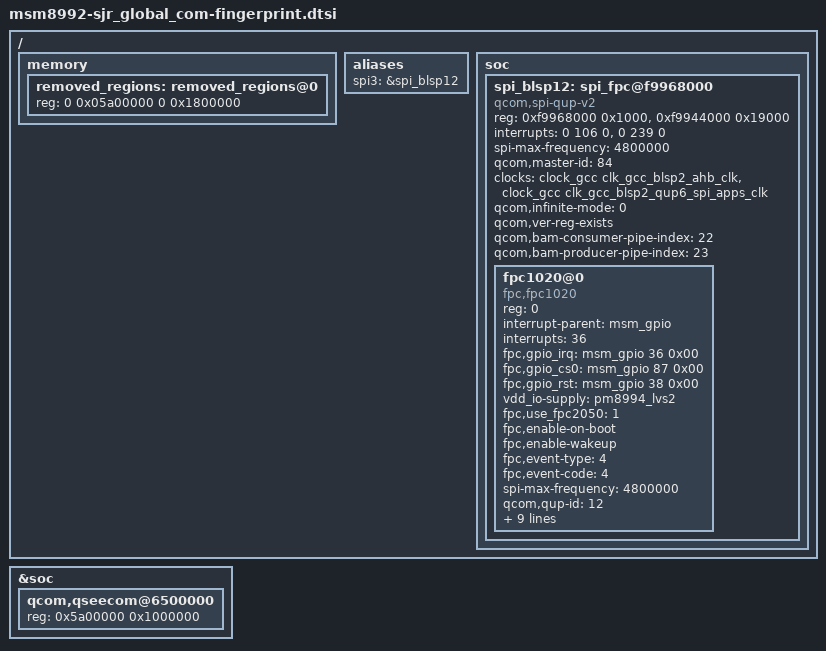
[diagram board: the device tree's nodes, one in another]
/*
 * Copyright (c) 2015, The Linux Foundation. All rights reserved.
 *
 * This program is free software; you can redistribute it and/or modify
 * it under the terms of the GNU General Public License version 2 and
 * only version 2 as published by the Free Software Foundation.
 *
 * This program is distributed in the hope that it will be useful,
 * but WITHOUT ANY WARRANTY; without even the implied warranty of
 * MERCHANTABILITY or FITNESS FOR A PARTICULAR PURPOSE.  See the
 * GNU General Public License for more details.
 */

&soc {
	/delete-node/ qcom,pcie@fc520000;
};

/ {
	memory {
		removed_regions: removed_regions@0 {
			reg = <0 0x05a00000 0 0x1800000>;
		};
	};

};

	&soc {
		qcom,qseecom@6500000 {
			reg = <0x5a00000 0x1000000>;
		};
	};



/ {
	aliases {
	spi3 = &spi_blsp12;
	};


	soc {
		spi_blsp12: spi_fpc@f9968000{    /* BLSP2 QUP5 */
			status = "ok";
			compatible = "qcom,spi-qup-v2";
			#address-cells = <1>;
			#size-cells = <0>;

			reg-names = "spi_physical", "spi_bam_physical";
			reg = <0xf9968000 0x1000>, <0xf9944000 0x19000>;

			interrupt-names = "spi_irq", "spi_bam_irq";
			interrupts = <0 106 0>, <0 239 0>;

			spi-max-frequency = <4800000>; /* TODO */
			qcom,master-id = <84>;

			clock-names = "iface_clk", "core_clk";
			clocks = <&clock_gcc clk_gcc_blsp2_ahb_clk>,
			<&clock_gcc clk_gcc_blsp2_qup6_spi_apps_clk>;

			/* Assign runtime functions to pins */

			/* only  REE
			qcom,use-pinctrl;
			pinctrl-names = "spi_default","spi_sleep";
			pinctrl-0 = <&spi_blsp12_active>;
			pinctrl-1 = <&spi_blsp12_suspend>;
			*/

			/* Need to be disable */
			/*
			qcom,gpio-mosi = <&msm_gpio 85 0>;
			qcom,gpio-miso = <&msm_gpio 86 0>;

			qcom,gpio-cs0 = <&msm_gpio 87 0>;
			qcom,gpio-clk = <&msm_gpio 88 0>;
			*/

			qcom,infinite-mode = <0>;
			/* qcom,use-bam; */
			qcom,ver-reg-exists;
			qcom,bam-consumer-pipe-index = <22>;
			qcom,bam-producer-pipe-index = <23>;

		};
	};
};

&spi_blsp12 {
	fpc1020@0 {
		status = "ok";
		reg = <0>;
		compatible = "fpc,fpc1020";
		interrupt-parent = <&msm_gpio>;
		interrupts = <36>;
		fpc,gpio_irq	=  <&msm_gpio 36 0x00>;
		fpc,gpio_cs0	= <&msm_gpio 87 0x00>;
		fpc,gpio_rst	= <&msm_gpio 38 0x00>;

		/*vcc_spi-supply  = <&pm8994_s4>;*/
		/*vdd_ana-supply  = <&pm8994_l32>;*/
		vdd_io-supply	= <&pm8994_lvs2>;
		fpc,use_fpc2050 = <1>;
		fpc,enable-on-boot;
		fpc,enable-wakeup;
		/* EV_MSC, MSC_SCAN */
		fpc,event-type = <4>;
		fpc,event-code = <4>;
		spi-max-frequency = <4800000>;
		qcom,qup-id = <12>;
		clock-names = "iface_clk", "core_clk";
		clocks = <&clock_gcc clk_gcc_blsp2_ahb_clk>,
			<&clock_gcc clk_gcc_blsp2_qup6_spi_apps_clk>;

		pinctrl-names = "fpc1020_spi_active",
					"fpc1020_reset_reset",
					"fpc1020_reset_active",
					"fpc1020_cs_low",
					"fpc1020_cs_high",
					"fpc1020_cs_active",
					"fpc1020_irq_active";

		pinctrl-0 = <&fpc_spi_active>;
		pinctrl-1 = <&fpc_reset_reset>;
		pinctrl-2 = <&fpc_reset_active>;
		pinctrl-3 = <&fpc_cs_low>;
		pinctrl-4 = <&fpc_cs_high>;
		pinctrl-5 = <&fpc_cs_active>;
		pinctrl-6 = <&fpc_irq_active>;
	};
};

